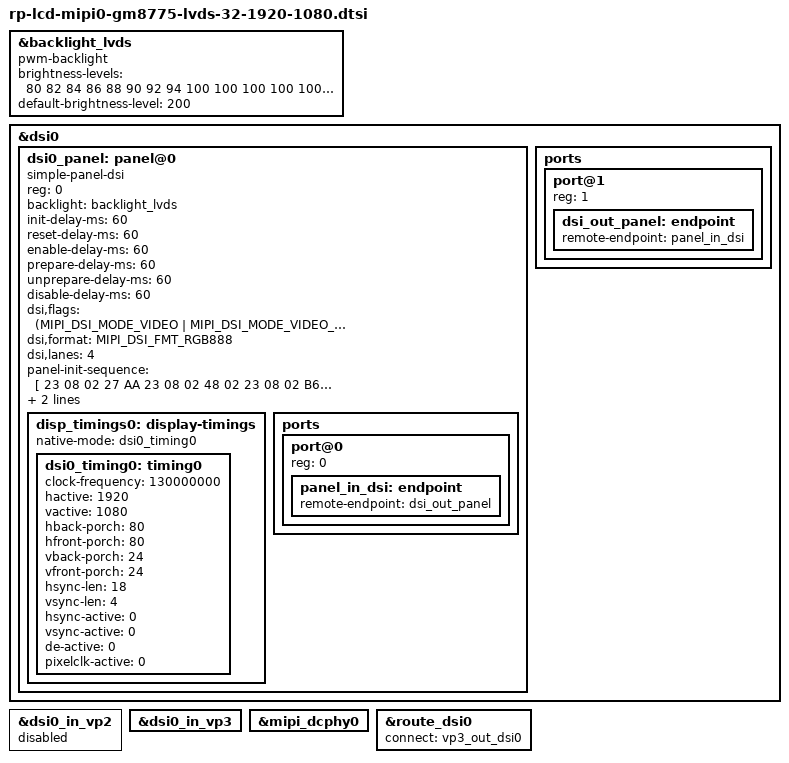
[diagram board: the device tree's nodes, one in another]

&backlight_lvds {
        compatible = "pwm-backlight";
        //pwms = <&pwm1 0 25000 0>;
        status = "okay";
        brightness-levels = <
/*
              0  20  20  21  21  22  22  23
             23  24  24  25  25  26  26  27
             27  28  28  29  29  30  30  31
             31  32  32  33  33  34  34  35
             35  36  36  37  37  38  38  39
             40  41  42  43  44  45  46  47
             48  49  50  51  52  53  54  55
             56  57  58  59  60  61  62  63
             64  65  66  67  68  69  70  71
             72  73  74  75  76  77  78  79
             80  81  82  83  84  85  86  87
             88  89  90  91  92  93  94  95
             96  97  98  99 100 101 102 103
            104 105 106 107 108 109 110 111
            112 113 114 115 116 117 118 119
            120 121 122 123 124 125 126 127
            128 129 130 131 132 133 134 135
            136 137 138 139 140 141 142 143
            144 145 146 147 148 149 150 151
            152 153 154 155 156 157 158 159
            160 161 162 163 164 165 166 167
            168 169 170 171 172 173 174 175
            176 177 178 179 180 181 182 183
            184 185 186 187 188 189 190 191
            192 193 194 195 196 197 198 199
            200 201 202 203 204 205 206 207
            208 209 210 211 212 213 214 215
            216 217 218 219 220 221 222 223
            224 225 226 227 228 229 230 231
            232 233 234 235 236 237 238 239
            240 241 242 243 244 245 246 247
            248 249 250 251 252 253 254 255
*/            
            
            80 82 84 86 88 90 92 94
            100 100 100 100 100 100 100 100
            110 110 110 110 110 110 110 110
            120 120 120 120 120 120 120 120
            130 130 130 130 130 130 130 130
            140 150 150 150 150 150 150 150
            170 170 170 170 170 170 170 170
            170 170 170 170 170 170 170 170
            180 180 180 180 180 180 180 180
            180 180 180 180 180 180 180 180
            190 190 190 190 190 190 190 190
            190 190 190 190 190 190 190 190
            200 200 200 200 200 200 200 200
            200 200 200 200 200 200 200 200
            200 200 200 200 200 200 200 200
            200 200 200 200 200 200 200 200
            200 200 200 200 200 200 200 200
            200 200 200 200 200 200 200 200
            200 200 200 200 200 200 200 200
            210 210 210 210 210 210 210 210
            220 220 220 220 220 220 220 220
            220 220 220 220 220 220 220 220
            220 220 220 220 220 220 220 220
            230 230 230 230 230 230 230 230
            230 230 230 230 230 230 230 230
            230 230 230 230 230 230 230 230
            240 240 240 240 240 240 240 240
            240 240 240 240 240 240 240 240
            240 240 240 240 240 240 240 240
            240 240 240 240 240 240 240 240
            240 241 242 243 244 245 246 247
            248 249 250 251 252 253 254 255
        >;
        default-brightness-level = <200>;
    };








&dsi0 {
    status = "okay";
//    rockchip,lane-rate = <480000>;
    dsi0_panel: panel@0 {
        status = "okay";
        compatible = "simple-panel-dsi";
        reg = <0>;

        //enable-gpios = <&gpio3 RK_PC6 GPIO_ACTIVE_LOW>;
        //reset-gpios = <&gpio4 RK_PC6 GPIO_ACTIVE_LOW>;
        //pinctrl-names = "default";
        //pinctrl-0 = <&lcd_rst_gpio>;

        backlight = <&backlight_lvds>;
    init-delay-ms = <60>;
        reset-delay-ms = <60>;
        enable-delay-ms = <60>;
        prepare-delay-ms = <60>;
        unprepare-delay-ms = <60>;
        disable-delay-ms = <60>;
        dsi,flags = <(MIPI_DSI_MODE_VIDEO | MIPI_DSI_MODE_VIDEO_BURST |
            MIPI_DSI_MODE_LPM | MIPI_DSI_MODE_EOT_PACKET)>;
        dsi,format = <MIPI_DSI_FMT_RGB888>;
        dsi,lanes  = <4>;
        
        panel-init-sequence = [
            
                        //mipi clk
                        23 08 02 27 AA
                        23 08 02 48 02
                        23 08 02 B6 20
                        23 08 02 01 80
                        23 08 02 02 38
                        23 08 02 03 47
                        23 08 02 04 50
                        23 08 02 05 12
                        23 08 02 06 50
                        23 08 02 07 00
                        23 08 02 08 18
                        23 08 02 09 04
                        23 08 02 0A 18
                        23 08 02 0B 82
                        23 08 02 0C 13
                        23 08 02 0D 01
                        23 08 02 0E 80
                        23 08 02 0F 20
                        23 08 02 10 20
                        23 08 02 11 03
                        23 08 02 12 1B
                        23 08 02 13 63
                        23 08 02 14 34
                        23 08 02 15 20
                        23 08 02 16 10
                        23 08 02 17 00
                        23 08 02 18 34
                        23 08 02 19 20
                        23 08 02 1A 10
                        23 08 02 1B 00
                        23 08 02 1E 46
                        23 08 02 51 30
                        23 08 02 1F 10
                        23 08 02 2A 01
                        
            05 78 01 11//delay 120MS
            05 78 01 29
        ];
        
        panel-exit-sequence = [
            05 78 01 28
            05 78 01 10
        ];

        disp_timings0: display-timings {
            native-mode = <&dsi0_timing0>;
            dsi0_timing0: timing0 {
                    clock-frequency = <130000000>;
                    hactive = <1920>;
                    vactive = <1080>;
                    hback-porch = <80>;
                    hfront-porch = <80>;
                    vback-porch = <24>;
                    vfront-porch = <24>;
                    hsync-len = <18>;
                    vsync-len = <4>;
                    hsync-active = <0>;
                    vsync-active = <0>;
                    de-active = <0>;
                    pixelclk-active = <0>;
            };
        };

        ports {
            #address-cells = <1>;
            #size-cells = <0>;

            port@0 {
                reg = <0>;
                panel_in_dsi: endpoint {
                    remote-endpoint = <&dsi_out_panel>;
                };
            };
        };
    };

    ports {
        #address-cells = <1>;
        #size-cells = <0>;

        port@1 {
            reg = <1>;
            dsi_out_panel: endpoint {
                remote-endpoint = <&panel_in_dsi>;
            };
        };
    };

};


&dsi0_in_vp2 {
    status = "disabled";
};

&dsi0_in_vp3 {
    status = "okay";
};

&mipi_dcphy0 {
    status = "okay";
};

&route_dsi0 {
    status = "okay";
    connect = <&vp3_out_dsi0>;
};



